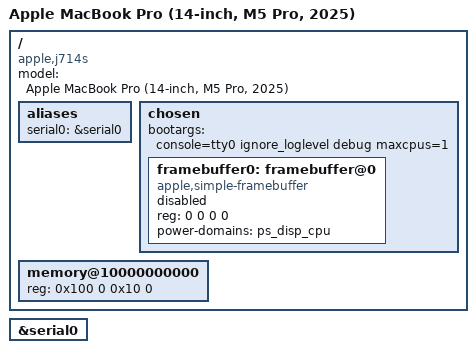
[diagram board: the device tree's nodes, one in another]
// SPDX-License-Identifier: GPL-2.0+ OR MIT
/*
 * Apple MacBook Pro (14-inch, M5 Pro, 2025) — j714sap / Mac17,9
 *
 * Boot-minimal board file. Untested on hardware.
 */

/dts-v1/;

#include "t6050-min.dtsi"

/ {
	compatible = "apple,j714s", "apple,t6050", "apple,arm-platform";
	model = "Apple MacBook Pro (14-inch, M5 Pro, 2025)";

	aliases {
		serial0 = &serial0;
	};

	chosen {
		#address-cells = <2>;
		#size-cells = <2>;
		ranges;

		/*
		 * Console MUST be tty0 (the framebuffer console). stdout-path =
		 * "serial0" sends the kernel log to the physical UART, which is
		 * not reachable on this machine — the screen then shows only the
		 * boot logo and no text.
		 * m1n1 does not set /chosen/bootargs, so this is the whole cmdline.
		 */
		/*
		 * maxcpus=1: Linux runs smp_init() BEFORE driver initcalls, so
		 * secondary CPU bringup happens before DRM/fbcon exists. If it
		 * hangs there, the screen stays blank with no way to see why.
		 * m1n1 already reports CPU start failures on T6050, so boot one
		 * core first — we can always add the rest back once there's a
		 * console to read.
		 */
		bootargs = "console=tty0 ignore_loglevel debug maxcpus=1";

		framebuffer0: framebuffer@0 {
			compatible = "apple,simple-framebuffer", "simple-framebuffer";
			reg = <0 0 0 0>; /* filled by m1n1 */
			power-domains = <&ps_disp_cpu>;
			/* format properties filled by m1n1 */
			status = "disabled";
		};
	};

	memory@10000000000 {
		device_type = "memory";
		reg = <0x100 0 0x10 0>; /* filled by m1n1 */
	};
};

&serial0 {
	status = "okay";
};
